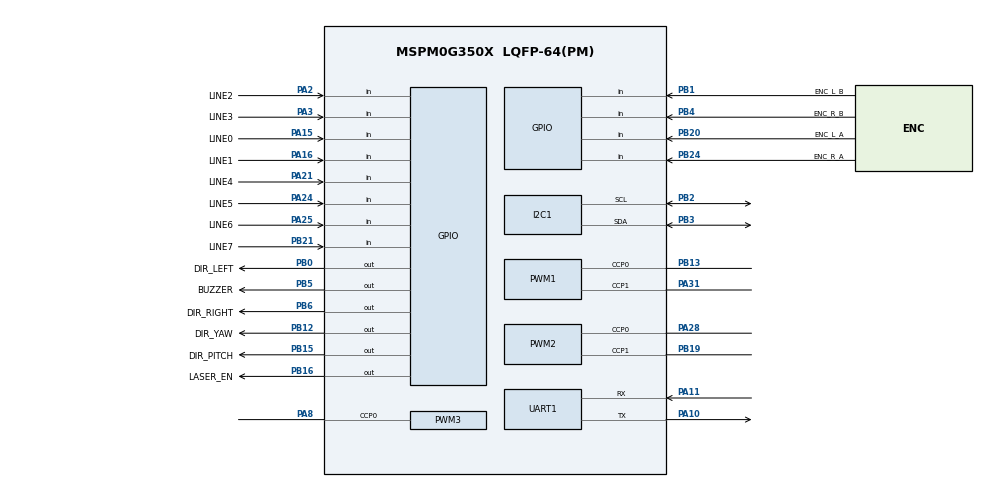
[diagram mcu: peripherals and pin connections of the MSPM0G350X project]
/**
 *
 * @cliArgs --device "MSPM0G350X" --part "Default" --package "LQFP-64(PM)" --product "mspm0_sdk@2.10.00.04"
 * @versions {"tool":"1.28.0+4696"}
 */

/**
 * Import the modules used in this configuration.
 */
const GPIO   = scripting.addModule("/ti/driverlib/GPIO", {}, false);
const GPIO1  = GPIO.addInstance();
const GPIO2  = GPIO.addInstance();
const GPIO3  = GPIO.addInstance();
const GPIO4  = GPIO.addInstance();
const GPIO5  = GPIO.addInstance();
const I2C    = scripting.addModule("/ti/driverlib/I2C", {}, false);
const I2C1   = I2C.addInstance();
const PWM    = scripting.addModule("/ti/driverlib/PWM", {}, false);
const PWM1   = PWM.addInstance();
const PWM2   = PWM.addInstance();
const PWM3   = PWM.addInstance();
const PWM4   = PWM.addInstance();
const SYSCTL = scripting.addModule("/ti/driverlib/SYSCTL");
const TIMER  = scripting.addModule("/ti/driverlib/TIMER", {}, false);
const TIMER1 = TIMER.addInstance();
const UART   = scripting.addModule("/ti/driverlib/UART", {}, false);
const UART1  = UART.addInstance();
const UART2  = UART.addInstance();

/**
 * Write custom configuration values to the imported modules.
 */
GPIO1.$name                         = "GPIO_MOTOR";
GPIO1.port                          = "PORTB";
GPIO1.associatedPins.create(2);
GPIO1.associatedPins[0].$name       = "DIR_LEFT";
GPIO1.associatedPins[0].ioStructure = "SD";
GPIO1.associatedPins[0].pin.$assign = "PB0";
GPIO1.associatedPins[1].$name       = "DIR_RIGHT";
GPIO1.associatedPins[1].ioStructure = "SD";
GPIO1.associatedPins[1].pin.$assign = "PB6";

const Board = scripting.addModule("/ti/driverlib/Board", {}, false);

GPIO2.$name                         = "GPIO_TURRET";
GPIO2.associatedPins.create(4);
GPIO2.associatedPins[0].$name       = "DIR_YAW";
GPIO2.associatedPins[0].ioStructure = "SD";
GPIO2.associatedPins[0].pin.$assign = "PB12";
GPIO2.associatedPins[1].$name       = "DIR_PITCH";
GPIO2.associatedPins[1].ioStructure = "SD";
GPIO2.associatedPins[1].pin.$assign = "PB15";
GPIO2.associatedPins[2].$name       = "LASER_EN";
GPIO2.associatedPins[2].ioStructure = "SD";
GPIO2.associatedPins[2].pin.$assign = "PB16";
GPIO2.associatedPins[3].$name       = "BUZZER";
GPIO2.associatedPins[3].ioStructure = "SD";
GPIO2.associatedPins[3].pin.$assign = "PB5";

GPIO3.$name                         = "GPIO_LINE";
GPIO3.associatedPins.create(8);
GPIO3.associatedPins[0].direction   = "INPUT";
GPIO3.associatedPins[0].$name       = "LINE0";
GPIO3.associatedPins[0].pin.$assign = "PA15";
GPIO3.associatedPins[1].$name       = "LINE1";
GPIO3.associatedPins[1].direction   = "INPUT";
GPIO3.associatedPins[1].pin.$assign = "PA16";
GPIO3.associatedPins[2].$name       = "LINE2";
GPIO3.associatedPins[2].direction   = "INPUT";
GPIO3.associatedPins[2].pin.$assign = "PA2";
GPIO3.associatedPins[3].$name       = "LINE3";
GPIO3.associatedPins[3].direction   = "INPUT";
GPIO3.associatedPins[3].pin.$assign = "PA3";
GPIO3.associatedPins[4].$name       = "LINE4";
GPIO3.associatedPins[4].direction   = "INPUT";
GPIO3.associatedPins[4].pin.$assign = "PA21";
GPIO3.associatedPins[5].$name       = "LINE5";
GPIO3.associatedPins[5].direction   = "INPUT";
GPIO3.associatedPins[5].pin.$assign = "PA24";
GPIO3.associatedPins[6].$name       = "LINE6";
GPIO3.associatedPins[6].direction   = "INPUT";
GPIO3.associatedPins[6].pin.$assign = "PA25";
GPIO3.associatedPins[7].$name       = "LINE7";
GPIO3.associatedPins[7].direction   = "INPUT";
GPIO3.associatedPins[7].pin.$assign = "PB21";

GPIO4.$name                         = "GPIO_ENCODER";
GPIO4.associatedPins.create(4);
GPIO4.associatedPins[0].$name       = "ENC_L_B";
GPIO4.associatedPins[0].direction   = "INPUT";
GPIO4.associatedPins[0].interruptEn = true;
GPIO4.associatedPins[0].polarity    = "RISE_FALL";
GPIO4.associatedPins[0].pin.$assign = "PB1";
GPIO4.associatedPins[1].$name       = "ENC_L_A";
GPIO4.associatedPins[1].direction   = "INPUT";
GPIO4.associatedPins[1].polarity    = "RISE_FALL";
GPIO4.associatedPins[1].interruptEn = true;
GPIO4.associatedPins[1].pin.$assign = "PB20";
GPIO4.associatedPins[2].$name       = "ENC_R_A";
GPIO4.associatedPins[2].direction   = "INPUT";
GPIO4.associatedPins[2].interruptEn = true;
GPIO4.associatedPins[2].polarity    = "RISE_FALL";
GPIO4.associatedPins[2].pin.$assign = "PB24";
GPIO4.associatedPins[3].$name       = "ENC_R_B";
GPIO4.associatedPins[3].direction   = "INPUT";
GPIO4.associatedPins[3].interruptEn = true;
GPIO4.associatedPins[3].polarity    = "RISE_FALL";
GPIO4.associatedPins[3].pin.$assign = "PB4";

GPIO5.$name                               = "GPIO_LED";
GPIO5.associatedPins[0].$name             = "LED_STATUS";
GPIO5.associatedPins[0].ioStructure       = "SD";
GPIO5.associatedPins[0].launchPadShortcut = "LED2RedEn";

I2C1.$name                             = "I2C_SENSOR_BUS";
I2C1.basicEnableController             = true;
I2C1.peripheral.$assign                = "I2C1";
I2C1.peripheral.sdaPin.$assign         = "PB3";
I2C1.peripheral.sclPin.$assign         = "PB2";
I2C1.sdaPinConfig.hideOutputInversion  = scripting.forceWrite(false);
I2C1.sdaPinConfig.onlyInternalResistor = scripting.forceWrite(false);
I2C1.sdaPinConfig.passedPeripheralType = scripting.forceWrite("Digital");
I2C1.sdaPinConfig.$name                = "ti_driverlib_gpio_GPIOPinGeneric2";
I2C1.sdaPinConfig.enableConfig         = true;
I2C1.sdaPinConfig.internalResistor     = "PULL_UP";
I2C1.sclPinConfig.hideOutputInversion  = scripting.forceWrite(false);
I2C1.sclPinConfig.onlyInternalResistor = scripting.forceWrite(false);
I2C1.sclPinConfig.passedPeripheralType = scripting.forceWrite("Digital");
I2C1.sclPinConfig.$name                = "ti_driverlib_gpio_GPIOPinGeneric3";
I2C1.sclPinConfig.enableConfig         = true;
I2C1.sclPinConfig.internalResistor     = "PULL_UP";

PWM1.$name                              = "PWM_MOTOR_LEFT";
PWM1.timerCount                         = 3200;
PWM1.peripheral.ccp0Pin.$assign         = "PB13";
PWM1.peripheral.ccp1Pin.$assign         = "PA31";
PWM1.PWM_CHANNEL_0.$name                = "ti_driverlib_pwm_PWMTimerCC0";
PWM1.PWM_CHANNEL_1.$name                = "ti_driverlib_pwm_PWMTimerCC1";
PWM1.ccp0PinConfig.direction            = scripting.forceWrite("OUTPUT");
PWM1.ccp0PinConfig.hideOutputInversion  = scripting.forceWrite(false);
PWM1.ccp0PinConfig.onlyInternalResistor = scripting.forceWrite(false);
PWM1.ccp0PinConfig.passedPeripheralType = scripting.forceWrite("Digital");
PWM1.ccp0PinConfig.$name                = "ti_driverlib_gpio_GPIOPinGeneric4";
PWM1.ccp1PinConfig.direction            = scripting.forceWrite("OUTPUT");
PWM1.ccp1PinConfig.hideOutputInversion  = scripting.forceWrite(false);
PWM1.ccp1PinConfig.onlyInternalResistor = scripting.forceWrite(false);
PWM1.ccp1PinConfig.passedPeripheralType = scripting.forceWrite("Digital");
PWM1.ccp1PinConfig.$name                = "ti_driverlib_gpio_GPIOPinGeneric5";

PWM2.$name                              = "PWM_MOTOR_RIGHT";
PWM2.timerCount                         = 3200;
PWM2.peripheral.$assign                 = "TIMG7";
PWM2.peripheral.ccp0Pin.$assign         = "PA28";
PWM2.peripheral.ccp1Pin.$assign         = "PB19";
PWM2.PWM_CHANNEL_0.$name                = "ti_driverlib_pwm_PWMTimerCC2";
PWM2.PWM_CHANNEL_1.$name                = "ti_driverlib_pwm_PWMTimerCC3";
PWM2.ccp0PinConfig.direction            = scripting.forceWrite("OUTPUT");
PWM2.ccp0PinConfig.hideOutputInversion  = scripting.forceWrite(false);
PWM2.ccp0PinConfig.onlyInternalResistor = scripting.forceWrite(false);
PWM2.ccp0PinConfig.passedPeripheralType = scripting.forceWrite("Digital");
PWM2.ccp0PinConfig.$name                = "ti_driverlib_gpio_GPIOPinGeneric6";
PWM2.ccp1PinConfig.direction            = scripting.forceWrite("OUTPUT");
PWM2.ccp1PinConfig.hideOutputInversion  = scripting.forceWrite(false);
PWM2.ccp1PinConfig.onlyInternalResistor = scripting.forceWrite(false);
PWM2.ccp1PinConfig.passedPeripheralType = scripting.forceWrite("Digital");
PWM2.ccp1PinConfig.$name                = "ti_driverlib_gpio_GPIOPinGeneric7";

PWM3.$name                              = "PWM_STEP_YAW";
PWM3.timerCount                         = 32000;
PWM3.ccIndex                            = [0];
PWM3.PWM_CHANNEL_0.$name                = "ti_driverlib_pwm_PWMTimerCC4";
PWM3.PWM_CHANNEL_0.dutyCycle            = 50;
PWM3.ccp0PinConfig.direction            = scripting.forceWrite("OUTPUT");
PWM3.ccp0PinConfig.hideOutputInversion  = scripting.forceWrite(false);
PWM3.ccp0PinConfig.onlyInternalResistor = scripting.forceWrite(false);
PWM3.ccp0PinConfig.passedPeripheralType = scripting.forceWrite("Digital");
PWM3.ccp0PinConfig.$name                = "ti_driverlib_gpio_GPIOPinGeneric8";
PWM3.peripheral.$assign                 = "TIMA0";
PWM3.peripheral.ccp0Pin.$assign         = "PA8";

PWM4.$name                              = "PWM_STEP_PITCH";
PWM4.timerCount                         = 32000;
PWM4.ccIndex                            = [0];
PWM4.PWM_CHANNEL_0.$name                = "ti_driverlib_pwm_PWMTimerCC6";
PWM4.PWM_CHANNEL_0.dutyCycle            = 50;
PWM4.ccp0PinConfig.direction            = scripting.forceWrite("OUTPUT");
PWM4.ccp0PinConfig.hideOutputInversion  = scripting.forceWrite(false);
PWM4.ccp0PinConfig.onlyInternalResistor = scripting.forceWrite(false);
PWM4.ccp0PinConfig.passedPeripheralType = scripting.forceWrite("Digital");
PWM4.ccp0PinConfig.$name                = "ti_driverlib_gpio_GPIOPinGeneric10";

SYSCTL.forceDefaultClkConfig = true;

TIMER1.$name       = "TIMER_CTRL_1KHZ";
TIMER1.timerMode   = "PERIODIC";
TIMER1.timerPeriod = "1 ms";
TIMER1.interrupts  = ["ZERO"];

UART1.$name                            = "UART_DEBUG";
UART1.targetBaudRate                   = 115200;
UART1.enableFIFO                       = true;
UART1.rxFifoThreshold                  = "DL_UART_RX_FIFO_LEVEL_ONE_ENTRY";
UART1.enableDMARX                      = false;
UART1.enableDMATX                      = false;
UART1.peripheral.$assign               = "UART0";
UART1.peripheral.rxPin.$assign         = "PA11";
UART1.peripheral.txPin.$assign         = "PA10";
UART1.txPinConfig.direction            = scripting.forceWrite("OUTPUT");
UART1.txPinConfig.hideOutputInversion  = scripting.forceWrite(false);
UART1.txPinConfig.onlyInternalResistor = scripting.forceWrite(false);
UART1.txPinConfig.passedPeripheralType = scripting.forceWrite("Digital");
UART1.txPinConfig.$name                = "ti_driverlib_gpio_GPIOPinGeneric0";
UART1.rxPinConfig.hideOutputInversion  = scripting.forceWrite(false);
UART1.rxPinConfig.onlyInternalResistor = scripting.forceWrite(false);
UART1.rxPinConfig.passedPeripheralType = scripting.forceWrite("Digital");
UART1.rxPinConfig.$name                = "ti_driverlib_gpio_GPIOPinGeneric1";

UART2.$name                            = "UART_K230";
UART2.targetBaudRate                   = 115200;
UART2.enableFIFO                       = true;
UART2.rxFifoThreshold                  = "DL_UART_RX_FIFO_LEVEL_ONE_ENTRY";
UART2.enabledInterrupts                = ["RX"];
UART2.txPinConfig.$name                = "ti_driverlib_gpio_GPIOPinGeneric9";
UART2.txPinConfig.direction            = scripting.forceWrite("OUTPUT");
UART2.txPinConfig.hideOutputInversion  = scripting.forceWrite(false);
UART2.txPinConfig.onlyInternalResistor = scripting.forceWrite(false);
UART2.txPinConfig.passedPeripheralType = scripting.forceWrite("Digital");
UART2.rxPinConfig.$name                = "ti_driverlib_gpio_GPIOPinGeneric11";
UART2.rxPinConfig.hideOutputInversion  = scripting.forceWrite(false);
UART2.rxPinConfig.onlyInternalResistor = scripting.forceWrite(false);
UART2.rxPinConfig.passedPeripheralType = scripting.forceWrite("Digital");

/**
 * Pinmux solution for unlocked pins/peripherals. This ensures that minor changes to the automatic solver in a future
 * version of the tool will not impact the pinmux you originally saw.  These lines can be completely deleted in order to
 * re-solve from scratch.
 */
Board.peripheral.$suggestSolution            = "DEBUGSS";
Board.peripheral.swclkPin.$suggestSolution   = "PA20";
Board.peripheral.swdioPin.$suggestSolution   = "PA19";
GPIO5.associatedPins[0].pin.$suggestSolution = "PB26";
PWM1.peripheral.$suggestSolution             = "TIMG12";
PWM4.peripheral.$suggestSolution             = "TIMG0";
PWM4.peripheral.ccp0Pin.$suggestSolution     = "PA12";
SYSCTL.peripheral.$suggestSolution           = "SYSCTL";
TIMER1.peripheral.$suggestSolution           = "TIMA1";
UART2.peripheral.$suggestSolution            = "UART1";
UART2.peripheral.rxPin.$suggestSolution      = "PA18";
UART2.peripheral.txPin.$suggestSolution      = "PA17";
